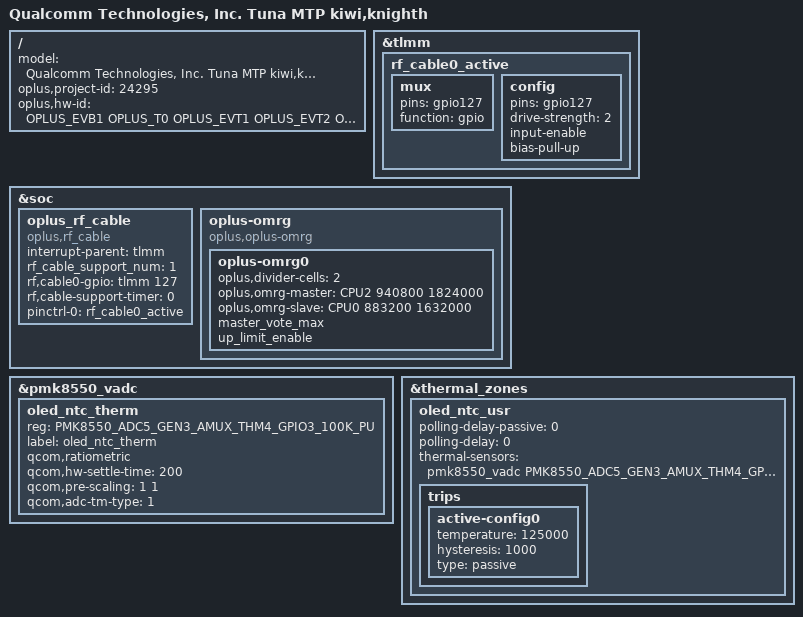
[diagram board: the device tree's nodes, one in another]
/dts-v1/;
/plugin/;
#include <dt-bindings/oplus/hw-id.h>
#include "../qcom/tuna-mtp-overlay.dts"
#include "oplus_nfc/kh_nfc.dtsi"
#include "tuna_overlay_common.dtsi"
#include "knighth_overlay_common.dtsi"
#include "oplus_misc/oplus-misc-24067.dtsi"
#include "oplus_chg/knighth/oplus-chg-24295.dtsi"
#include "oplus_fp/oplus_fp_24067_24295.dtsi"
#include "oplus_cam/aw37004.dtsi"
#include "sensor/knighth-sensor-24067-24295.dtsi"
#include "tp/knight-oplus-tp-24067.dtsi"
#include <dt-bindings/iio/qcom,spmi-adc5-gen3-pmk8550.h>

/ {
    model = "Qualcomm Technologies, Inc. Tuna MTP kiwi,knighth";

    oplus,project-id = <24295>;
    oplus,hw-id = <OPLUS_EVB1 OPLUS_T0 OPLUS_EVT1 OPLUS_EVT2 OPLUS_DVT1 OPLUS_DVT2 OPLUS_PVT1>;
};

&tlmm {
  //#ifdef OPLUS_FEATURE_RF_CABLE_DETECT
  rf_cable0_active: rf_cable0_active {
    mux {
      pins = "gpio127";
      function = "gpio";
    };
    config {
      pins = "gpio127";
      drive-strength = <2>;
      input-enable;
      bias-pull-up;
    };
  };
  //#endif /* OPLUS_FEATURE_RF_CABLE_DETECT */
};

&soc {
  //#ifdef OPLUS_FEATURE_RF_CABLE_DETECT
  oplus_rf_cable {
    compatible = "oplus,rf_cable";
    interrupt-parent = <&tlmm>;
    rf_cable_support_num = <1>;
    rf,cable0-gpio = <&tlmm 127 0>;
    rf,cable-support-timer = <0>;
    pinctrl-names = "rf_cable_active";
    pinctrl-0 = <&rf_cable0_active>;
  };
  //#endif /* OPLUS_FEATURE_RF_CABLE_DETECT */

  //#ifdef CONFIG_OPLUS_OMRG
    oplus-omrg {
        compatible = "oplus,oplus-omrg";
        oplus-omrg0 {
                oplus,divider-cells = <2>;
                oplus,omrg-master = <&CPU2 940800 1824000>;
                oplus,omrg-slave = <&CPU0 883200 1632000>;
                master_vote_max;
                up_limit_enable;
                /* down_limit_enable; */
                /* thermal_enable; */
        };
    };
    //#endif
};

&pmk8550_vadc {
	oled_ntc_therm {
		reg = <PMK8550_ADC5_GEN3_AMUX_THM4_GPIO3_100K_PU>;
		label = "oled_ntc_therm";
		qcom,ratiometric;
		qcom,hw-settle-time = <200>;
		qcom,pre-scaling = <1 1>;
		qcom,adc-tm-type = <1>;
	};

};

&thermal_zones {
	oled_ntc_usr {
		polling-delay-passive = <0>;
		polling-delay = <0>;
		thermal-sensors = <&pmk8550_vadc PMK8550_ADC5_GEN3_AMUX_THM4_GPIO3_100K_PU>;
		trips {
			active-config0 {
				temperature = <125000>;
				hysteresis = <1000>;
				type = "passive";
			};
		};
	};
};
